# TLE9278 register map
Vendor: Infineon; File version: 0.1
Registers are 8-bit, read-write, no defined reset value unless marked. A register's access mark holds for its fields unless they carry their own. Offsets are from the block's base; [hi:lo] are bit positions; 'fields as' and 'values as' point back to an identical list.

## STAT — Status
Base 0x00000040
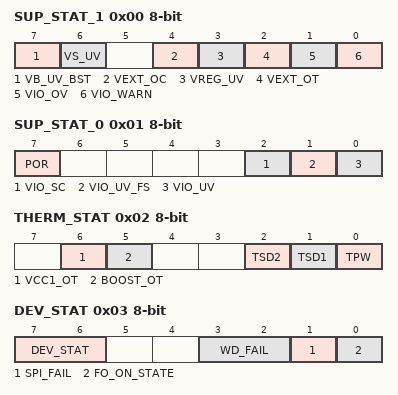
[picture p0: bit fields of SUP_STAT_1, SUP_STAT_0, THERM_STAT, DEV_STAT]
0x00 SUP_STAT_1 ro — Supply Voltage Fail Status
  [7] VB_UV_BST — VBSENSE low voltage detection
    0=not_detected (No VBSENSE low voltage detected); 1=detected (VBSENSE low voltage detected)
  [6] VS_UV — VS Under-Voltage Detection (VS,UV)
    0=not_detected (No VS undervoltage detected); 1=detected (VS undervoltage detected)
  [4] VEXT_OC — VEXT Over Current Detection
    0=not_detected (No OC); 1=detected (OC detected)
  [3] VREG_UV — VEXT Over Current Detection
    0=not_detected (No VEXT UV detection (PCFG OPEN); No VCC1 UV detection (PCFG connected to GND)); 1=detected (VEXT UV Fail detected (PCFG OPEN); VCC1 UV Fail detected (PCFG connected to GND))
  [2] VEXT_OT — VEXT Over Temperature Detection
    0=not_detected (No over temperature); 1=detected (VEXT over temperature detected)
  [1] VIO_OV — VIO Over Voltage Detection (VIO,OV,r)
    0=not_detected (No VIO overvoltage warning); 1=detected (VIO overvoltage detected)
  [0] VIO_WARN — VIO Undervoltage Prewarning (VPW,f)
    0=not_detected (No VIO undervoltage prewarning); 1=detected (VIO undervoltage prewarning detected)
0x01 SUP_STAT_0 ro — Supply Voltage Fail Status
  [7] POR — Power-On Reset Detection
    0=not_detected (No POR); 1=detected (POR occurred)
  [2] VIO_SC — VIO Short to GND Detection
    0=not_detected (No short); 1=detected (VCC1 short to GND detected)
  [1] VIO_UV_FS — VIO UV-Detection (due to VRTx reset)
    0=not_detected (No Fail-Safe Mode entry due to 4th consecutive VIO_UV); 1=detected (Fail-Safe Mode entry due to 4th consecutive VIO_UV)
  [0] VIO_UV — VIO UV-Detection (due to VRTx reset)
    0=not_detected (No VIO_UV detection); 1=detected (VIO UV-Fail detected)
0x02 THERM_STAT ro — Thermal Protection Status
  [6] VCC1_OT — VCC1 Over temperature detection
    0=not_detected (No VCC1 overtemperature); 1=detected (VCC1 overtemperature detected)
  [5] BOOST_OT — Boost Over temperature detection
    0=not_detected (No Boost overtemperature); 1=detected (Boost overtemperature detected)
  [2] TSD2 — TSD2 Thermal Shut-Down Detection
    0=not_detected (No TSD2 event); 1=detected (TSD2 OT detected - leading to SBC Fail-Safe Mode)
  [1] TSD1 — TSD1 Thermal Shut-Down Detection
    0=not_detected (No TSD1 fail); 1=detected (TSD1 OT detected)
  [0] TPW — Thermal Pre Warning
    0=not_detected (No Thermal Pre warning); 1=detected (Thermal Pre warning detected)
0x03 DEV_STAT ro — Device Information Status
  [7:6] DEV_STAT — Device Status before Restart Mode
    0=Cleared (Register must be actively cleared); 1=failure (Restart due to failure described in Table 8 and Table 9); 2=Sleep_Mode
  [3:2] WD_FAIL — Number of WD-Failure Events (1/2 WD failures depending on INTN)
    0=not_detected (No WD Fail); 1=1x WD Fail, FO activation - Config 1/2 selected; 2=2x WD Fail, FO activation - Config 3/4 selected
  [1] SPI_FAIL — SPI Fail Information
    0=not_detected (No SPI fail); 1=detected (Invalid SPI command detected)
  [0] FO_ON_STATE — Activation of Fail Output FO
    0=not_detected (No Failure); 1=detected (Failure occurred)
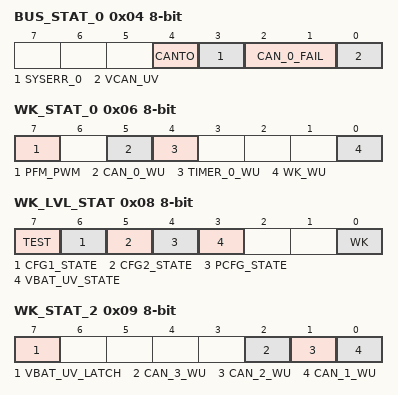
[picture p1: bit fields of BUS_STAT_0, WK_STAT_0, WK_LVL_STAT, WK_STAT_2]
0x04 BUS_STAT_0 ro — Bus Communication Status
  [4] CANTO — CAN_0 Time Out Detection
    0=not_detected (Normal operation); 1=detected (CAN Time Out detected)
  [3] SYSERR_0 — SWK System Error
    0=not_detected (Selective Wake Mode is possible); 1=detected (System Error detected, SWK enabling not possible)
  [2:1] CAN_0_FAIL — CAN Failure Status
    0=none (No error); 1=TSD_shutdown (CAN TSD shutdown); 2=TXD_DOM (CAN_TXD_DOM: TXD dominant time out for more than 2ms); 3=BUS_DOM (CAN_BUS_DOM: BUS dominant time out for more than 2ms)
  [0] VCAN_UV — Under voltage CAN Bus Supply
    0=detected (Normal operation); 1=not_detected (CAN Supply undervoltage detected. Transmitter disabled)
0x06 WK_STAT_0 ro — Wake-up Source and Information Status 0
  [7] PFM_PWM — PFM_PWM automatic transition detected
    0=not_detected (No automatic PFM_PWM transition detected); 1=detected (Automatic PFM_PWM transition detected)
  [5] CAN_0_WU — Wake up via CAN Bus
    0=not_detected (No Wake up); 1=detected (Wake up)
  [4] TIMER_0_WU — Wake up via cyclic wake
    0=not_detected (No Wake up); 1=detected (Wake up)
  [0] WK_WU — Wake up via WK
    0=not_detected (No Wake up); 1=detected (Wake up)
0x08 WK_LVL_STAT ro — WK Input Level
  [7] TEST — Status of TEST Pin
    0=User-Mode (Default SBC user mode operation); 1=Development-Mode (Software Development Mode, no reset triggered due to wrong Watchdog trigger)
  [6] CFG1_STATE — Status of INTN Pin
    0=LOW Level; Fail-Safe Mode entered due to WD failure (1 or 2 failure) depending on CFG2 bit) Config 2/4; 1=HIGH Level; Fail-Safe Mode not entered, due to WD failure, Config 1/3
  [5] CFG2_STATE — Status of CFG2 bit on HW_CTRL_0 register
    0=LOW Level (=0), Fail Outputs (FOx) are active after 2nd watchdog trigger fail Config 3/4; 1=HIGH Level (=1); Fail Outputs (FOx) are active after 1st watchdog trigger fail Config 1/2
  [4] PCFG_STATE — Status of PCFG Pin
    0=LOW Level; the VEXT is fix at 3.3V and it has to be connected to VIO to supply the microcontroller (connected to GND); 1=HIGH Level; the microcontroller is supplied from the VCC1 and VIO=VCC1. The VEXT is fully configurable (left OPEN)
  [3] VBAT_UV_STATE — VBSENSE Under-Voltage Detection Status
    0=not_detected (No VBSENSE undervoltage detected); 1=detected (VBSENSE undervoltage detected)
  [0] WK — Status of WK
    0=Low Level (=0); 1=High Level (=1)
0x09 WK_STAT_2 ro — Wake-up Source and Information Status 2
  [7] VBAT_UV_LATCH — VBSENSE Under-Voltage Detection
    0=not-detected (No VBSENSE undervoltage detected); 1=detected (VBSENSE undervoltage detected (latched status))
  [2] CAN_3_WU — Wake up via CAN_3 Bus
    0=no_wake_up; 1=wake-up
  [1] CAN_2_WU — Wake up via CAN_2 Bus
    0=no_wake_up; 1=wake-up
  [0] CAN_1_WU — Wake up via CAN_1 Bus
    0=no_wake_up; 1=wake-up
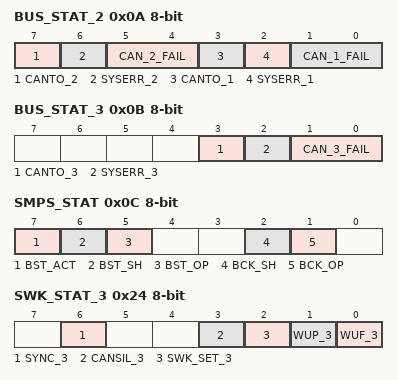
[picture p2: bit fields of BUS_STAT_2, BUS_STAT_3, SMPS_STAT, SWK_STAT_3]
0x0A BUS_STAT_2 ro — Bus Communication Status 2
  [7] CANTO_2 — CAN_2 Time Out Detection
    values as BUS_STAT_0.CANTO
  [6] SYSERR_2 — CAN_2 SWK System Error
    values as BUS_STAT_0.SYSERR_0
  [5:4] CAN_2_FAIL — CAN_2 Failure Status
    0=not_detected (No error); 1=CAN_TSD (CAN TSD shutdown); 2=CAN_TXD_DOM(10) (CAN_TXD_DOM: TXD dominant time out for more than 2ms); 3=CAN_BUS_DOM (11) (CAN_BUS_DOM: BUS dominant time out for more than 2ms)
  [3] CANTO_1 — CAN_1 Time Out Detection
    values as BUS_STAT_0.CANTO
  [2] SYSERR_1 — CAN_1 SWK System Error
    values as BUS_STAT_0.SYSERR_0
  [1:0] CAN_1_FAIL — CAN_1 Failure Status
    0=not_detected (No error); 1=CAN TSD shutdown (Wake up); 2=CAN_TXD_DOM (CAN_TXD_DOM: TXD dominant time out for more than 2ms); 3=CAN_BUS_DOM (CAN_BUS_DOM: BUS dominant time out for more than 2ms)
0x0B BUS_STAT_3 ro — Bus Communication Status 3
  [3] CANTO_3 — CAN_3 Time Out Detection
    values as BUS_STAT_0.CANTO
  [2] SYSERR_3 — CAN_3 SWK System Error
    values as BUS_STAT_0.SYSERR_0
  [1:0] CAN_3_FAIL — CAN_3 Failure Status
    values as BUS_STAT_2.CAN_1_FAIL
0x0C SMPS_STAT ro — Bus Communication Status 3
  [7] BST_ACT — Boost Regulator Active
    0=not_active (Boost not active); 1=active (Boost active)
  [6] BST_SH — BSTD short detection
    0=not_detected (No short detected on BSTD pin); 1=detected (BSTD short to GND)
  [5] BST_OP — BSTD open detection
    0=not_detected (No open detected on BSTD pin); 1=detected (BSTD loss of diode detected or loss of Boost GND)
  [2] BCK_SH — BCKSW pin short detection
    0=not_detected (No BCKSW short detected); 1=detected (SShort to GND or short to VS detected on BCKSW pin)
  [1] BCK_OP — BCKSW pin open detection
    0=No BCKSW open detected (not-detected); 1=BCKSW open detected (detected)
0x24 SWK_STAT_3 ro — Selective Wake Status CAN_3
  [6] SYNC_3 — CAN_3 Synchronisation (at least one CAN frame without fail must have been received)
    0=failed (SWK function not working or not synchronous to CAN bus); 1=Valid CAN frame received, SWK function is synchronous to CAN_3 bus
  [3] CANSIL_3 — CAN_3 Silent Time during SWK operation
    0=not_exceeded (tsilence not exceeded); 1=exceeded (set if tsilence is exceeded)
  [2] SWK_SET_3 — CAN_3 Selective Wake Activity
    0=not_activated (Selective Wake is not active); 1=activated (Selective Wake is activated)
  [1] WUP_3 — CAN_3 Wake-up Pattern Detection
    0=not_detected (No WUP); 1=detected (WUP detected)
  [0] WUF_3 — CAN_3 SWK Wake-up Frame Detection (acc. ISO 11898-6)
    0=not_detected (No WUF); 1=detected (WUF detected)
0x25 SWK_ECNT_STAT_3 ro — SWK Error Counter Status CAN_3
  [5:0] ECNT_3 — SWK CAN_3 Frame Error Counter
    0=No Frame Error; 31=31 Frame Errors have been counted; 32=overflow (Error counter overflow - SWK function will be disabled)
0x26 SWK_CDR_STAT_3_1 ro — CDR Status CAN_3_1
  [7:0] NAVG_SAT_3 — Output Value from Filter Block
0x27 SWK_CDR_STAT_3_0 ro — CDR Status CAN_3_0
  [7:4] NAVG_SAT_3 — Output Value from Filter Block
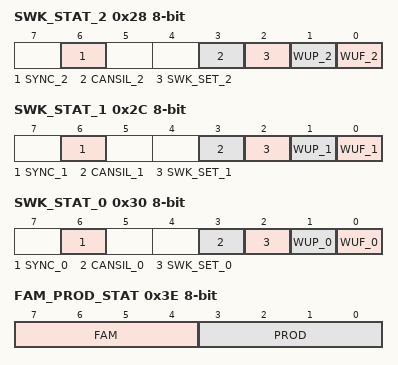
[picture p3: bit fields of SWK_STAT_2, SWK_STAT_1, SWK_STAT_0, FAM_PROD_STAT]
0x28 SWK_STAT_2 ro — Selective Wake Status CAN_2
  [6] SYNC_2 — CAN_2 Synchronisation (at least one CAN frame without fail must have been received)
    0=not_synchronous (SWK function not working or not synchronous to CAN bus); 1=synchronous (Valid CAN frame received, SWK function is synchronous to CAN_2 bus)
  [3] CANSIL_2 — CAN_2 Silent Time during SWK operation
    values as SWK_STAT_3.CANSIL_3
  [2] SWK_SET_2 — CAN_2 Selective Wake Activity
    0=not_active (Selective Wake is not active); 1=active (Selective Wake is activated)
  [1] WUP_2 — CAN_2 Wake-up Pattern Detection
    0=not_detected (No WUP); 1=detected (WUP detected)
  [0] WUF_2 — CAN_2 SWK Wake-up Frame Detection (acc. ISO 11898-6)
    0=not_detected (No WUF); 1=detected (WUF detected)
0x29 SWK_ECNT_STAT_2 ro — SWK Error Counter Status CAN_2
  [5:0] ECNT_2 — SWK CAN_2 Frame Error Counter
    0=not_detected (No Frame Error); 31=31_errors (31 Frame Errors have been counted); 32=overflow (Error counter overflow - SWK function will be disabled)
0x2A SWK_CDR_STAT_2_1 ro — CDR Status CAN_2_1
  [7:0] NAVG_SAT_2 — Output Value from Filter Block
0x2B SWK_CDR_STAT_2_0 ro — CDR Status CAN_2_0
  [7:4] NAVG_SAT_2 — Output Value from Filter Block
0x2C SWK_STAT_1 ro — Selective Wake Status CAN_1
  [6] SYNC_1 — CAN_1 Synchronisation (at least one CAN frame without fail must have been received)
    0=not_synchronous (SWK function not working or not synchronous to CAN bus); 1=synchronous (Valid CAN frame received, SWK function is synchronous to CAN_1 bus)
  [3] CANSIL_1 — CAN_1 Silent Time during SWK operation
    values as SWK_STAT_3.CANSIL_3
  [2] SWK_SET_1 — CAN_1 Selective Wake Activity
    0=not_actived (Selective Wake is not active); 1=actived (Selective Wake is activated)
  [1] WUP_1 — CAN_1 Wake-up Pattern Detection
    0=not_detected (No WUP); 1=detected (WUP detected)
  [0] WUF_1 — CAN_1 SWK Wake-up Frame Detection (acc. ISO 11898-6)
    0=not_detected (No WUF); 1=detected (WUF detected)
0x2D SWK_ECNT_STAT_1 ro — SWK Error Counter Status CAN_1
  [5:0] ECNT_1 — SWK CAN_1 Frame Error Counter
    values as SWK_ECNT_STAT_2.ECNT_2
0x2E SWK_CDR_STAT_1_1 ro — SWK Error Counter Status CAN_1
  [7:0] NAVG_SAT_1 — Output Value from Filter Block
0x2F SWK_CDR_STAT_1_0 ro — CDR Status CAN_1_0
  [7:4] NAVG_SAT_1 — Output Value from Filter Block
0x30 SWK_STAT_0 ro — Selective Wake Status CAN_0
  [6] SYNC_0 — CAN_0 Synchronisation (at least one CAN frame without fail must have been received)
    0=not_synchronous (SWK function not working or not synchronous to CAN bus); 1=synchronous (Valid CAN frame received, SWK function is synchronous to CAN_0 bus)
  [3] CANSIL_0 — CAN_0 Silent Time during SWK operation
    values as SWK_STAT_3.CANSIL_3
  [2] SWK_SET_0 — CAN_0 Selective Wake Activity
    values as SWK_STAT_1.SWK_SET_1
  [1] WUP_0 — CAN_0 Wake-up Pattern Detection
    0=not_detected (No WUP); 1=detected (WUP detected)
  [0] WUF_0 — CAN_0 SWK Wake-up Frame Detection (acc. ISO 11898-6)
    0=not_detected (No WUF); 1=detected (WUF detected)
0x31 SWK_ECNT_STAT_0 ro — SWK Error Counter Status CAN_0
  [5:0] ECNT_0 — SWK CAN_0 Frame Error Counter
    values as SWK_ECNT_STAT_2.ECNT_2
0x32 SWK_CDR_STAT_0_1 ro — CDR Status CAN_0_1
  [7:0] NAVG_SAT_0 — Output Value from Filter Block
0x33 SWK_CDR_STAT_0_0 ro — CDR Status CAN_0_0
  [7:4] NAVG_SAT_0 — Output Value from Filter Block
0x3E FAM_PROD_STAT ro — Family and Product Identification Register
  [7:4] FAM — SBC Family Identifier (bit4=LSB; bit7=MSB)
    1=HERA (Driver SBC Family (HERA)); 2=HERCULES (DC/DC-SBC Family (HERCULES)); 3=ATHENA (Mid-Range SBC Family (ATHENA)); 4=MCP (Multi-CAN SBC Family (MCP)); 5=LITE (LITE SBC Family (LITE)); 7=ATHENA+ (Mid-Range+ SBC Family (ATHENA+))
  [3:0] PROD — SBC Product Identifier (bit0=LSB; bit3=MSB)
    4=TLE9461ES (TLE9461ES (VCC1 = 5V, no SWK)); 5=TLE9461ESV33 (TLE9461ESV33 (VCC1 = 3.3V, no SWK)); 6=TLE9461-3ES (TLE9461-3ES (VCC1 = 5V, SWK) (default value if device is not fused)); 7=TLE9461-3ESV33 (TLE9461-3ESV33 (VCC1 = 3.3V, SWK)); 12=TLE9471ES (TLE9471ES (VCC1 = 5V, no SWK)); 13=TLE9471ESV33 (TLE9471ESV33 (VCC1 = 3.3V, no SWK)); 14=TLE9471-3ES (TLE9471-3ES(VCC1 = 5V, SWK)); 15=TLE9471-3ESV33 (TLE9471-3ESV33 (VCC1 = 3.3V, SWK))
